AUTOSAR XML (schema 4-0-3)
standard types defined: UInt8
package /AUTOSAR_Platform/DataConstrs
  range DC_UInt8: raw 0..255
package /PATAC/Facility/DataTypes/Implementation
  unit NoUnit: factor-si-to-unit=1, offset-si-to-unit=0
package /PATAC/MSM/ModeAdjust
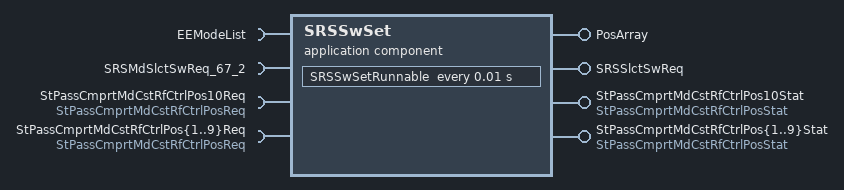
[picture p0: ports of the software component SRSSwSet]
  application sw component type SRSSwSet
    12 x provide port:
      PosArray: nonqueued-sender-com-spec{data-element=PosArray/Val, init-value=11 x 0}, provided-interface=PosArray
      SRSSlctSwReq: nonqueued-sender-com-spec{data-element=SRSSlctSwReq/Val, init-value=0}, provided-interface=SRSSlctSwReq
      StPassCmprtMdCstRfCtrlPos10Stat: nonqueued-sender-com-spec{data-element=StPassCmprtMdCstRfCtrlPosStat/Val, init-value=0}, provided-interface=StPassCmprtMdCstRfCtrlPosStat
      StPassCmprtMdCstRfCtrlPos{1..9}Stat: nonqueued-sender-com-spec{data-element=StPassCmprtMdCstRfCtrlPosStat/Val, init-value=0}, provided-interface=StPassCmprtMdCstRfCtrlPosStat
    12 x require port:
      EEModeList: required-com-specs=[Get, Set], required-interface=EEModeList
      SRSMdSlctSwReq_67_2: nonqueued-receiver-com-spec{data-element=SRSMdSlctSwReq_67_2/Val, filter=data-filter-type=ALWAYS, init-value=0}, required-interface=SRSMdSlctSwReq_67_2
      StPassCmprtMdCstRfCtrlPos10Req: nonqueued-receiver-com-spec{data-element=StPassCmprtMdCstRfCtrlPosReq/Val, filter=data-filter-type=ALWAYS, init-value=0}, required-interface=StPassCmprtMdCstRfCtrlPosReq
      StPassCmprtMdCstRfCtrlPos{1..9}Req: nonqueued-receiver-com-spec{data-element=StPassCmprtMdCstRfCtrlPosReq/Val, filter=data-filter-type=ALWAYS, init-value=0}, required-interface=StPassCmprtMdCstRfCtrlPosReq
    behavior SRSSwSet_InternalBehavior
      timing event TMT_SRSSwSetRunnable: start-on-event=SRSSwSetRunnable, period=0.01
      runnable SRSSwSetRunnable: minimum-start-interval=0.01
        data-receive-point-by-arguments:
          11 x access:
            REC_SRSMdSlctSwReq_67_2_Val: accessed-variable=SRSMdSlctSwReq_67_2.Val
            REC_StPassCmprtMdCstRfCtrlPos10Req_Val: accessed-variable=StPassCmprtMdCstRfCtrlPos10Req.Val
            REC_StPassCmprtMdCstRfCtrlPos{1..9}Req_Val: accessed-variable=StPassCmprtMdCstRfCtrlPos{1..9}Req.Val
        data-send-points:
          12 x access:
            SEND_PosArray_Val: accessed-variable=PosArray.Val
            SEND_SRSSlctSwReq_Val: accessed-variable=SRSSlctSwReq.Val
            SEND_StPassCmprtMdCstRfCtrlPos10Stat_Val: accessed-variable=StPassCmprtMdCstRfCtrlPos10Stat.Val
            SEND_StPassCmprtMdCstRfCtrlPos{1..9}Stat_Val: accessed-variable=StPassCmprtMdCstRfCtrlPos{1..9}Stat.Val
        sync call SC_EEModeList_Get: operation=EEModeList.Get, timeout=0
        sync call SC_EEModeList_Set: operation=EEModeList.Set, timeout=0
  swc implementation SRSSwSet_Implementation: behavior=SRSSwSet_InternalBehavior
    code-descriptors:
      code Default: artifact-descriptors=autosar-engineering-object={short-label=Default, category=SWSRC}
package /PATAC/MSM/ModeAdjust/DataType
  5 x impl type, all with sw-calibration-access=READ-ONLY, type-emitter=RTE:
    ModeList: category=ARRAY
      element Val: array-size=11, array-size-semantics=FIXED-SIZE, implementation-data-type=UInt8
    RfCtrlPosReq: category=VALUE, base-type=UInt8, compu {0=NoAction, 1..32=Mode1..Mode32, 33=NoMode}
    RfCtrlPosStat:
      category=VALUE
      base-type=UInt8
      compu {0=NoModeSet, 1=Mode1Set, 2=Mode2Set, 3=Mode3Set, 4=Mode4Set, 5=Mode5Set, 6=Mode6Set, 7=Mode7Set, 8=Mode8Set, 9=Mode9Set, 10=Mode10Set, 11=Mode11Set, 12=Mode12Set, 13=Mode13Set, 14=Mode14Set, 15=Mode15Set, 16=Mode16Set, 17=Mode17Set, 18=Mode18Set, 19=Mode19Set, 20=Mode20Set, 21=Mode21Set, 22=Mode22Set, 23=Mode23Set, 24=Mode24Set, 25=Mode25Set, 26=Mode26Set, 27=Mode27Set, 28=Mode28Set, 29=Mode29Set, 30=Mode30Set, 31=Mode31Set, 32=Mode32Set}
    SRSMode1:
      category=VALUE
      base-type=UInt8
      compu {0=SRSSlctSwStat_None, 1=SRSSlctSwStat_EzeEntry, 2=SRSSlctSwStat_EzeExt, 3=SRSSlctSwStat_LfVip, 4=SRSSlctSwStat_RtVip, 5=SRSSlctSwStat_AllVip, 6=SRSSlctSwStat_LfLug, 7=SRSSlctSwStat_RtLug, 8=SRSSlctSwStat_AllLug, 9=SRSSlctSwStat_IntimacyL, 10=SRSSlctSwStat_FamilyR, 11=SRSSlctSwStat_FamilyL, 12=SRSSlctSwStat_RcvyL, 13=SRSSlctSwStat_RcvyR, 14=SRSSlctSwStat_LyingL, 15=SRSSlctSwStat_LyingR, 16=SRSSlctSwStat_LgrstOpenLt, 17=SRSSlctSwStat_LgrstCloseLt, 18=SRSSlctSwStat_LgrstOpenRt, 19=SRSSlctSwStat_LgrstCloseRt, 20=SRSSlctSwStat_IntimacyR}
    SRSSlctSwStat1: category=VALUE, base-type=UInt8, compu {0=NoSwitchSelected, 1=Switch1Mode, 2=Switch2Mode, 3=Switch3Mode, 4=Switch4Mode, 5=Switch5Mode, 6=Switch6Mode, 7=Switch7Mode, 8=Switch8Mode, 9=Switch9Mode, 10=Switch10Mode, 11=Reserved}
package /PATAC/MSM/ModeAdjust/PortInterface
  client server interface EEModeList
    operation Get
      arg arg: type=ModeList, direction=OUT, server-argument-impl-policy=USE-ARGUMENT-TYPE
    operation Set
      arg arg: type=ModeList, direction=IN, server-argument-impl-policy=USE-ARGUMENT-TYPE
  5 x sender receiver interface:
    PosArray: invalidation-policy{data-element=PosArray/Val, handle-invalid=DONT-INVALIDATE}
      data Val: type=ModeList
    SRSMdSlctSwReq_67_2: invalidation-policy{data-element=SRSMdSlctSwReq_67_2/Val, handle-invalid=DONT-INVALIDATE}
      data Val: type=SRSSlctSwStat1
    SRSSlctSwReq: invalidation-policy{data-element=SRSSlctSwReq/Val, handle-invalid=DONT-INVALIDATE}
      data Val: type=SRSMode1
    StPassCmprtMdCstRfCtrlPosReq: invalidation-policy{data-element=StPassCmprtMdCstRfCtrlPosReq/Val, handle-invalid=DONT-INVALIDATE}
      data Val: type=RfCtrlPosReq
    StPassCmprtMdCstRfCtrlPosStat: invalidation-policy{data-element=StPassCmprtMdCstRfCtrlPosStat/Val, handle-invalid=DONT-INVALIDATE}
      data Val: type=RfCtrlPosStat
